# LPC18xx register map
File version: 0.23
CPU: CM3 r0p0, little endian, no MPU, no FPU, 3 interrupt priority bits
Registers are 32-bit, read-write, reset 0x0 unless marked. A register's access mark holds for its fields unless they carry their own. Offsets are from the block's base; [hi:lo] are bit positions; {n}, {i} and the like mark numbered series; 'fields as' and 'values as' point back to an identical list.

## USART0 — USART0_2_3
Base 0x40081000
Same registers: USART2 0x400C1000, USART3 0x400C2000
0x00 RBR ro reset not defined read-modifies — Receiver Buffer Register. Contains the next received character to be read (DLAB = 0).
  [7:0] RBR — Receiver buffer. The USART Receiver Buffer Register contains the oldest received byte in the USART RX FIFO.
0x00 THR wo reset not defined read-modifies (alternate view of RBR) — Transmit Holding Register. The next character to be transmitted is written here (DLAB = 0).
  [7:0] THR — Transmit Holding Register. Writing to the USART Transmit Holding Register causes the data to be stored in the USART transmit FIFO. The byte will be sent when it reaches the bottom of the FIFO and the transmitter is available.
0x00 DLL reset 0x1 (alternate view of RBR) — Divisor Latch LSB. Least significant byte of the baud rate divisor value. The full divisor is used to generate a baud rate from the fractional rate divider (DLAB = 1).
  [7:0] DLLSB — Divisor latch LSB. The USART Divisor Latch LSB Register, along with the DLM register, determines the baud rate of the USART.
0x04 DLM — Divisor Latch MSB. Most significant byte of the baud rate divisor value. The full divisor is used to generate a baud rate from the fractional rate divider (DLAB = 1).
  [7:0] DLMSB — Divisor latch MSB. The USART Divisor Latch MSB Register, along with the DLL register, determines the baud rate of the USART.
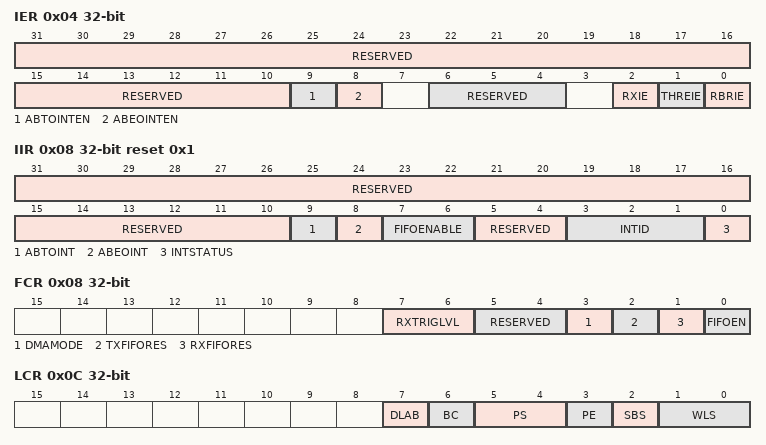
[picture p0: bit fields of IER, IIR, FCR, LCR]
0x04 IER (alternate view of DLM) — Interrupt Enable Register. Contains individual interrupt enable bits for the 7 potential USART interrupts (DLAB = 0).
  [31:10] RESERVED — Reserved, user software should not write ones to reserved bits. The value read from a reserved bit is not defined.
  [9] ABTOINTEN — Enables the auto-baud time-out interrupt.
    0=DISABLE (Disable. Disable auto-baud time-out Interrupt.); 1=ENABLE (Enable. Enable auto-baud time-out Interrupt.)
  [8] ABEOINTEN — Enables the end of auto-baud interrupt.
    0=DISABLE (Disable. Disable end of auto-baud Interrupt.); 1=ENABLE (Enable. Enable end of auto-baud Interrupt.)
  [6:4] RESERVED — Reserved, user software should not write ones to reserved bits. The value read from a reserved bit is not defined.
  [2] RXIE — RX Line Interrupt Enable. Enables the USART RX line status interrupts. The status of this interrupt can be read from LSR[4:1].
    0=DISABLE (Disable. Disable the RX line status interrupts.); 1=ENABLE (Enable. Enable the RX line status interrupts.)
  [1] THREIE — THRE Interrupt Enable. Enables the THRE interrupt for USART. The status of this interrupt can be read from LSR[5].
    0=DISABLE (Disable. Disable the THRE interrupt.); 1=ENABLE (Enable. Enable the THRE interrupt.)
  [0] RBRIE — RBR Interrupt Enable. Enables the Receive Data Available interrupt for USART. It also controls the Character Receive Time-out interrupt.
    0=DISABLE (Disable. Disable the RDA interrupt.); 1=ENABLE (Enable. Enable the RDA interrupt.)
0x08 IIR ro reset 0x1 — Interrupt ID Register. Identifies which interrupt(s) are pending.
  [31:10] RESERVED — Reserved, user software should not write ones to reserved bits. The value read from a reserved bit is not defined.
  [9] ABTOINT — Auto-baud time-out interrupt. True if auto-baud has timed out and interrupt is enabled.
  [8] ABEOINT — End of auto-baud interrupt. True if auto-baud has finished successfully and interrupt is enabled.
  [7:6] FIFOENABLE — Copies of FCR[0].
  [5:4] RESERVED — Reserved, user software should not write ones to reserved bits. The value read from a reserved bit is not defined.
  [3:1] INTID — Interrupt identification. IER[3:1] identifies an interrupt corresponding to the USART Rx FIFO. All other combinations of IER[3:1] not listed below are reserved (100,101,111).
    3=RLS (RLS. Priority 1 (highest). (Highest) Receive Line Status (RLS).); 2=RDA (RDA. Priority 2 - Receive Data Available (RDA).); 6=CTI (CTI. Priority 2 - Character Time-out Indicator (CTI).); 1=THRE (THRE. Priority 3 - THRE Interrupt.)
  [0] INTSTATUS — Interrupt status. Note that IIR[0] is active low. The pending interrupt can be determined by evaluating IIR[3:1].
    0=INTERRUPT_PENDING (Interrupt pending. At least one interrupt is pending.); 1=NOT_PENDING (Not pending. No interrupt is pending.)
0x08 FCR wo — FIFO Control Register. Controls USART FIFO usage and modes.
  [7:6] RXTRIGLVL — RX Trigger Level. These two bits determine how many receiver USART FIFO characters must be written before an interrupt is activated.
    0=LEVEL_0 (Level 0. Trigger level 0 (1 character or 0x01).); 1=LEVEL_1 (Level 1. Trigger level 1 (4 characters or 0x04).); 2=LEVEL_2 (Level 2. Trigger level 2 (8 characters or 0x08).); 3=LEVEL_3 (Level 3. Trigger level 3 (14 characters or 0x0E).)
  [5:4] RESERVED — Reserved, user software should not write ones to reserved bits. The value read from a reserved bit is not defined.
  [3] DMAMODE — DMA Mode Select. When the FIFO enable bit (bit 0 of this register) is set, this bit selects the DMA mode.
  [2] TXFIFORES — TX FIFO Reset.
    0=NO_EFFECT (No effect. No impact on either of USART FIFOs.); 1=CLEAR (Clear. Writing a logic 1 to FCR[2] will clear all bytes in USART TX FIFO, reset the pointer logic. This bit is self-clearing.)
  [1] RXFIFORES — RX FIFO Reset.
    0=NO_EFFECT (No effect. No impact on either of USART FIFOs.); 1=CLEAR (Clear. Writing a logic 1 to FCR[1] will clear all bytes in USART Rx FIFO, reset the pointer logic. This bit is self-clearing.)
  [0] FIFOEN — FIFO Enable.
    0=DISABLED (Disabled. USART FIFOs are disabled. Must not be used in the application.); 1=ENABLED (Enabled. Active high enable for both USART Rx and TX FIFOs and FCR[7:1] access. This bit must be set for proper USART operation. Any transition on this bit will automatically clear the USART FIFOs.)
0x0C LCR — Line Control Register. Contains controls for frame formatting and break generation.
  [7] DLAB — Divisor Latch Access Bit.
    0=DISABLED (Disabled. Disable access to Divisor Latches.); 1=ENABLED (Enabled. Enable access to Divisor Latches.)
  [6] BC — Break Control.
    0=DISABLED (Disabled. Disable break transmission.); 1=ENABLED (Enabled. Enable break transmission. Output pin USART TXD is forced to logic 0 when LCR[6] is active high.)
  [5:4] PS — Parity Select.
    0=ODD_PARITY (Odd parity. Number of 1s in the transmitted character and the attached parity bit will be odd.); 1=EVEN_PARITY (Even Parity. Number of 1s in the transmitted character and the attached parity bit will be even.); 2=FORCE_HIGH (Force HIGH. Forced 1 stick parity.); 3=FORCE_LOW (Force LOW. Forced 0 stick parity.)
  [3] PE — Parity Enable
    0=DISABLE_PARITY_GENER (Disable parity generation and checking.); 1=ENABLE_PARITY_GENERA (Enable parity generation and checking.)
  [2] SBS — Stop Bit Select.
    0=1_STOP_BIT; 1=2_STOP_BITS_1 (2 stop bits (1.5 if LCR[1:0]=00).)
  [1:0] WLS — Word Length Select.
    {v}={v+5}_BIT_CHARACTER_LENG ({v+5}-bit character length.) (v=0..3)
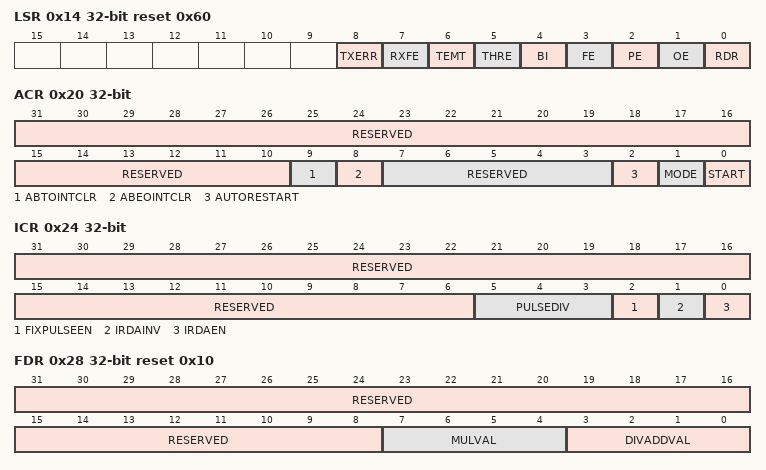
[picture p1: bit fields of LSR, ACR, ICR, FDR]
0x14 LSR ro reset 0x60 read-modifies — Line Status Register. Contains flags for transmit and receive status, including line errors.
  [8] TXERR — Error in transmitted character. A NACK response is given by the receiver in Smart card T=0 mode. This bit is cleared when the LSR register is read.
    0=NO_ERROR (No error. No error (normal default condition).); 1=NACK (NACK. A NACK response is received during Smart card T=0 operation.)
  [7] RXFE — Error in RX FIFO. LSR[7] is set when a character with a RX error such as framing error, parity error or break interrupt, is loaded into the RBR. This bit is cleared when the LSR register is read and there are no subsequent errors in the USART FIFO.
    0=NO_ERROR (No error. RBR contains no USART RX errors or FCR[0]=0.); 1=ERROR (Error. USART RBR contains at least one USART RX error.)
  [6] TEMT — Transmitter Empty. TEMT is set when both THR and TSR are empty; TEMT is cleared when either the TSR or the THR contain valid data.
    0=NOT_EMPTY (Not empty. THR and/or the TSR contains valid data.); 1=EMPTY (Empty. THR and the TSR are empty.)
  [5] THRE — Transmitter Holding Register Empty. THRE is set immediately upon detection of an empty USART THR and is cleared on a THR write.
    0=NOT_EMPTY (Not empty. THR contains valid data.); 1=EMPTY (Empty. THR is empty.)
  [4] BI — Break Interrupt. When RXD1 is held in the spacing state (all zeros) for one full character transmission (start, data, parity, stop), a break interrupt occurs. Once the break condition has been detected, the receiver goes idle until RXD1 goes to marking state (all ones). A LSR read clears this status bit. The time of break detection is dependent on FCR[0]. Note: The break interrupt is associated with the character at the top of the USART RBR FIFO.
    0=INACTIVE (Inactive. Break interrupt status is inactive.); 1=ACTIVE (Active. Break interrupt status is active.)
  [3] FE — Framing Error. When the stop bit of a received character is a logic 0, a framing error occurs. A LSR read clears LSR[3]. The time of the framing error detection is dependent on FCR0. Upon detection of a framing error, the RX will attempt to re-synchronize to the data and assume that the bad stop bit is actually an early start bit. However, it cannot be assumed that the next received byte will be correct even if there is no Framing Error. Note: A framing error is associated with the character at the top of the USART RBR FIFO.
    0=INACTIVE (Inactive. Framing error status is inactive.); 1=ACTIVE (Active. Framing error status is active.)
  [2] PE — Parity Error. When the parity bit of a received character is in the wrong state, a parity error occurs. A LSR read clears LSR[2]. Time of parity error detection is dependent on FCR[0]. Note: A parity error is associated with the character at the top of the USART RBR FIFO.
    0=INACTIVE (Inactive. Parity error status is inactive.); 1=ACTIVE (Active. Parity error status is active.)
  [1] OE — Overrun Error. The overrun error condition is set as soon as it occurs. A LSR read clears LSR[1]. LSR[1] is set when USART RSR has a new character assembled and the USART RBR FIFO is full. In this case, the USART RBR FIFO will not be overwritten and the character in the USART RSR will be lost.
    0=INACTIVE (Inactive. Overrun error status is inactive.); 1=ACTIVE (Active. Overrun error status is active.)
  [0] RDR — Receiver Data Ready. LSR[0] is set when the RBR holds an unread character and is cleared when the USART RBR FIFO is empty.
    0=EMPTY (Empty. RBR is empty.); 1=DATA (Data. RBR contains valid data.)
0x1C SCR — Scratch Pad Register. Eight-bit temporary storage for software.
  [7:0] PAD — Scratch pad. A readable, writable byte.
0x20 ACR — Auto-baud Control Register. Contains controls for the auto-baud feature.
  [31:10] RESERVED — Reserved, user software should not write ones to reserved bits. The value read from a reserved bit is not defined.
  [9] ABTOINTCLR — Auto-baud time-out interrupt clear bit (write-only).
    0=NO_EFFECT (No effect. Writing a 0 has no impact.); 1=CLEAR (Clear. Writing a 1 will clear the corresponding interrupt in the IIR.)
  [8] ABEOINTCLR — End of auto-baud interrupt clear bit (write-only).
    values as ABTOINTCLR
  [7:3] RESERVED — Reserved, user software should not write ones to reserved bits. The value read from a reserved bit is not defined.
  [2] AUTORESTART — Restart bit.
    0=NO_RESTART; 1=RESTART (Restart. Restart in case of time-out (counter restarts at next USART Rx falling edge))
  [1] MODE — Auto-baud mode select bit.
  [0] START — Start bit. This bit is automatically cleared after auto-baud completion.
    0=STOP (Stop. Auto-baud stop (auto-baud is not running).); 1=START (Start. Auto-baud start (auto-baud is running). Auto-baud run bit. This bit is automatically cleared after auto-baud completion.)
0x24 ICR — IrDA control register (USART3 only)
  [31:6] RESERVED — Reserved, user software should not write ones to reserved bits. The value read from a reserved bit is not defined.
  [5:3] PULSEDIV — Configures the pulse when FixPulseEn = 1. See Table 885 for details.
  [2] FIXPULSEEN — IrDA fixed pulse width mode.
    0=DISABLED (Disabled. IrDA fixed pulse width mode disabled.); 1=ENABLED (Enabled. IrDA fixed pulse width mode enabled.)
  [1] IRDAINV — Serial input direction.
    0=NOT_INVERTED (Not inverted. The serial input is not inverted.); 1=INVERTED (Inverted. The serial input is inverted. This has no effect on the serial output.)
  [0] IRDAEN — IrDA mode enable.
    0=DISABLED (Disabled. IrDA mode on USART3 is disabled, USART3 acts as a standard USART.); 1=ENABLED (Enabled. IrDA mode on USART3 is enabled.)
0x28 FDR reset 0x10 — Fractional Divider Register. Generates a clock input for the baud rate divider.
  [31:8] RESERVED — Reserved, user software should not write ones to reserved bits. The value read from a reserved bit is not defined.
  [7:4] MULVAL — Baud rate pre-scaler multiplier value. This field must be greater or equal 1 for USART to operate properly, regardless of whether the fractional baud rate generator is used or not.
  [3:0] DIVADDVAL — Baud rate generation pre-scaler divisor value. If this field is 0, fractional baud rate generator will not impact the USART baud rate.
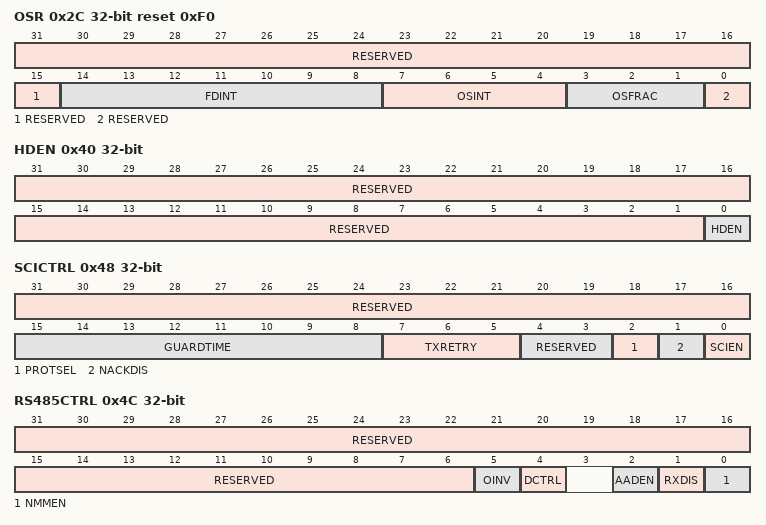
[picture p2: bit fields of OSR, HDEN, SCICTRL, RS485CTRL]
0x2C OSR reset 0xF0 — Oversampling Register. Controls the degree of oversampling during each bit time.
  [31:15] RESERVED — Reserved, user software should not write ones to reserved bits. The value read from a reserved bit is not defined.
  [14:8] FDINT — In Smart Card mode, these bits act as a more-significant extension of the OSint field, allowing an oversampling ratio up to 2048 as required by ISO7816-3. In Smart Card mode, bits 14:4 should initially be set to 371, yielding an oversampling ratio of 372.
  [7:4] OSINT — Integer part of the oversampling ratio, minus 1. The reset values equate to the normal operating mode of 16 input clocks per bit time.
  [3:1] OSFRAC — Fractional part of the oversampling ratio, in units of 1/8th of an input clock period. (001 = 0.125, ..., 111 = 0.875)
  [0] RESERVED — Reserved, user software should not write ones to reserved bits. The value read from a reserved bit is not defined.
0x40 HDEN reset not defined — Half-duplex enable Register
  [31:1] RESERVED — Reserved, user software should not write ones to reserved bits. The value read from a reserved bit is not defined.
  [0] HDEN — Half-duplex mode enable
    0=DISABLED (Disabled. Disable half-duplex mode.); 1=ENABLED (Enabled. Enable half-duplex mode.)
0x48 SCICTRL — Smart card interface control register
  [31:16] RESERVED — Reserved, user software should not write ones to reserved bits. The value read from a reserved bit is not defined.
  [15:8] GUARDTIME — Extra guard time. No extra guard time (0x0) results in a standard guard time as defined in ISO 7816-3, depending on the protocol type. A guard time of 0xFF indicates a minimal guard time as defined for the selected protocol.
  [7:5] TXRETRY — Maximum number of retransmissions in case of a negative acknowledge (protocol T=0). When the retry counter is exceeded, the USART will be locked until the FIFO is cleared. A TX error interrupt is generated when enabled.
  [4:3] RESERVED — Reserved, user software should not write ones to reserved bits. The value read from a reserved bit is not defined.
  [2] PROTSEL — Protocol selection as defined in the ISO7816-3 standard.
    0=T_EQ_0 (T = 0); 1=T_EQ_1 (T = 1)
  [1] NACKDIS — NACK response disable. Only applicable in T=0.
    0=ENABLED (Enabled. A NACK response is enabled.); 1=DISABLED (Disabled. A NACK response is inhibited.)
  [0] SCIEN — Smart Card Interface Enable.
    0=DISABLED (Disabled. Smart card interface disabled.); 1=ENABLED (Enabled. synchronous half duplex smart card interface is enabled.)
0x4C RS485CTRL — RS-485/EIA-485 Control. Contains controls to configure various aspects of RS-485/EIA-485 modes.
  [31:6] RESERVED — Reserved, user software should not write ones to reserved bits. The value read from a reserved bit is not defined.
  [5] OINV — Direction control pin polarity. This bit reverses the polarity of the direction control signal on the DIR pin.
    0=LOW (Low. The direction control pin will be driven to logic 0 when the transmitter has data to be sent. It will be driven to logic 1 after the last bit of data has been transmitted.); 1=HIGH (High. The direction control pin will be driven to logic 1 when the transmitter has data to be sent. It will be driven to logic 0 after the last bit of data has been transmitted.)
  [4] DCTRL — Direction control for DIR pin.
    0=DISABLED (Disabled. Disable Auto Direction Control.); 1=ENABLED (Enabled. Enable Auto Direction Control.)
  [2] AADEN — AAD enable
    0=DISABLED (Disabled. Auto Address Detect (AAD) is disabled.); 1=ENABLED (Enabled. Auto Address Detect (AAD) is enabled.)
  [1] RXDIS — Receiver enable.
    0=ENABLED (Enabled. The receiver is enabled.); 1=DISABLED (Disabled.The receiver is disabled.)
  [0] NMMEN — NMM enable.
    0=DISABLED (Disabled. RS-485/EIA-485 Normal Multidrop Mode (NMM) is disabled.); 1=ENABLED (Enabled. RS-485/EIA-485 Normal Multidrop Mode (NMM) is enabled. In this mode, an address is detected when a received byte causes the USART to set the parity error and generate an interrupt.)
0x50 RS485ADRMATCH — RS-485/EIA-485 address match. Contains the address match value for RS-485/EIA-485 mode.
  [7:0] ADRMATCH — Contains the address match value.
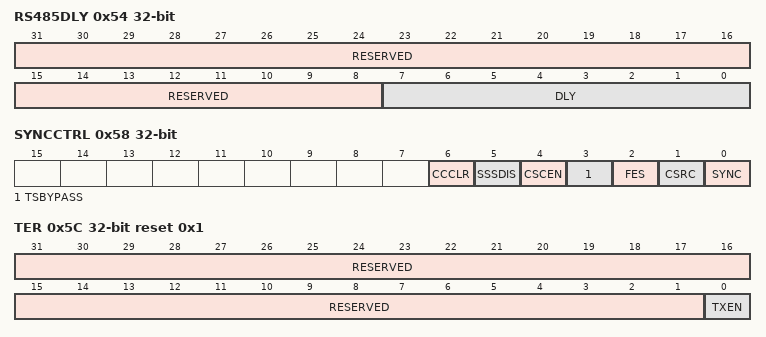
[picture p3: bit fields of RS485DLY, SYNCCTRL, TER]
0x54 RS485DLY — RS-485/EIA-485 direction control delay.
  [31:8] RESERVED — Reserved, user software should not write ones to reserved bits. The value read from a reserved bit is not defined.
  [7:0] DLY — Contains the direction control delay value. This register works in conjunction with an 8-bit counter.
0x58 SYNCCTRL — Synchronous mode control register.
  [6] CCCLR — Continuous clock clear
    0=SOFTWARE (Software. CSCEN is under software control.); 1=HARDWARE (Hardware. Hardware clears CSCEN after each character is received.)
  [5] SSSDIS — Start/stop bits
    0=SEND (Send. Send start and stop bits as in other modes.); 1=DO_NOT_SEND (Do not send. Do not send start/stop bits.)
  [4] CSCEN — Continuous master clock enable (used only when CSRC is 1)
    0=ON_CHARACTER (On character. SCLK cycles only when characters are being sent on TxD.); 1=CONTINUOUSLY (Continuously. SCLK runs continuously (characters can be received on RxD independently from transmission on TxD).)
  [3] TSBYPASS — Transmit synchronization bypass in synchronous slave mode.
    0=SYNCHRONIZED (Synchronized. The input clock is synchronized prior to being used in clock edge detection logic.); 1=NOT_SYNCHRONIZED (Not synchronized. The input clock is not synchronized prior to being used in clock edge detection logic. This allows for a high er input clock rate at the expense of potential metastability.)
  [2] FES — Edge sampling.
    0=RISING (Rising. RxD is sampled on the rising edge of SCLK.); 1=FALLING (Falling. RxD is sampled on the falling edge of SCLK.)
  [1] CSRC — Clock source select.
    0=SLAVE_MODE (Slave mode. Synchronous slave mode (SCLK in)); 1=MASTER_MODE (Master mode. Synchronous master mode (SCLK out))
  [0] SYNC — Enables synchronous mode.
    0=DISABLED; 1=ENABLED
0x5C TER reset 0x1 — Transmit Enable Register. Turns off USART transmitter for use with software flow control.
  [31:1] RESERVED — Reserved, user software should not write ones to reserved bits. The value read from a reserved bit is not defined.
  [0] TXEN — Transmit enable. After reset transmission is enabled. When the TXEN bit is de-asserted, no data will be transmitted although data may be pending in the TSR or THR.
